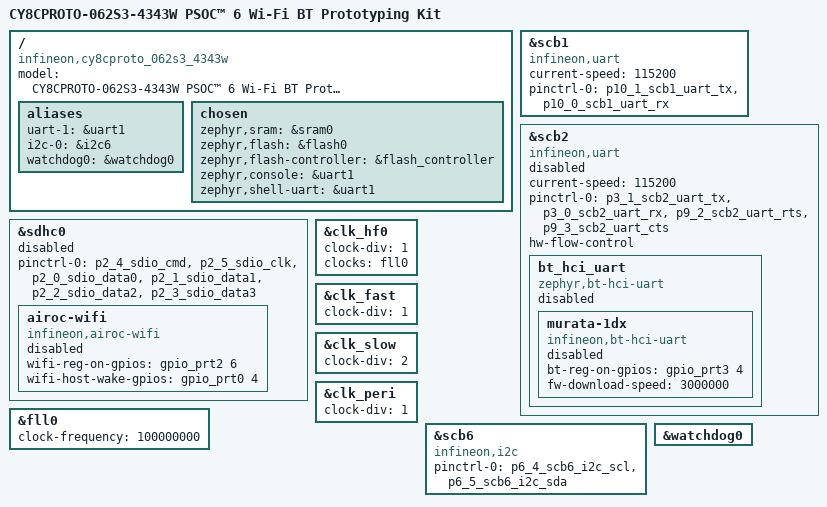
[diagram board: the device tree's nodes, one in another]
/*
 * Copyright (c) 2025 Hari Udayakumar <hariudkmr@gmail.com>
 * SPDX-License-Identifier: Apache-2.0
 */

/dts-v1/;
#include <infineon/cat1a/mpns/CY8C6245LQI_S3D72.dtsi>
#include <infineon/cat1a/system_clocks.dtsi>
#include "cy8cproto_062s3_4343w-common.dtsi"
#include "cy8cproto_062s3_4343w-pinctrl.dtsi"

/ {
	compatible = "infineon,cy8cproto_062s3_4343w", "cypress,PSOC6";
	model = "CY8CPROTO-062S3-4343W PSOC™ 6 Wi-Fi BT Prototyping Kit";

	aliases {
		uart-1 = &uart1;
		i2c-0 = &i2c6;
		watchdog0 = &watchdog0;
	};

	chosen {
		zephyr,sram = &sram0;
		zephyr,flash = &flash0;
		zephyr,flash-controller = &flash_controller;
		zephyr,console = &uart1;
		zephyr,shell-uart = &uart1;
	};
};

uart1: &scb1 {
	compatible = "infineon,uart";
	current-speed = <115200>;

	pinctrl-0 = <&p10_1_scb1_uart_tx &p10_0_scb1_uart_rx>;
	pinctrl-names = "default";
	status = "okay";
};

/*
 * The onboard Murata LBEE5KL1DX (CYW4343W) Wi-Fi/BT combo module is present
 * on this board, but Wi-Fi/BT is descoped from this board definition: the
 * Wi-Fi firmware blob alone (~420KB) does not fit alongside an application
 * in this SoC's 512KB internal flash. The HCI-UART and SDIO/Wi-Fi nodes
 * below are kept as disabled hardware-reference scaffolding only.
 */
uart2: &scb2 {
	compatible = "infineon,uart";

	/* The UART bus speed (current_speed) for zephyr_bt_uart should be the same
	 * as the default baudrate defined in CYW43xx firmware (default 115200).
	 */
	current-speed = <115200>;

	/* HCI-UART pins */
	pinctrl-0 = <&p3_1_scb2_uart_tx &p3_0_scb2_uart_rx &p9_2_scb2_uart_rts &p9_3_scb2_uart_cts>;
	pinctrl-names = "default";

	/* HW Flow control must be enabled for HCI H4 */
	hw-flow-control;
	status = "disabled";

	bt_hci_uart: bt_hci_uart {
		compatible = "zephyr,bt-hci-uart";
		status = "disabled";

		murata-1dx {
			compatible = "infineon,bt-hci-uart";
			bt-reg-on-gpios = <&gpio_prt3 4 GPIO_ACTIVE_HIGH>;

			/* Configuration UART speeds for firmware download (fw-download-speed)
			 * and HCI operation (hci-operation-speed).
			 * If hci-operation-speed or fw-download-speed are not defined in
			 * bt-hci{...} node, cyw43xx driver will use bus/current-speed as
			 * default speed.
			 */
			fw-download-speed = <3000000>;
			status = "disabled";
		};
	};
};

&sdhc0 {

	/* SDIO pins */
	pinctrl-0 = <&p2_4_sdio_cmd &p2_5_sdio_clk &p2_0_sdio_data0
		     &p2_1_sdio_data1 &p2_2_sdio_data2 &p2_3_sdio_data3>;
	pinctrl-names = "default";
	status = "disabled";

	/* Wi-Fi configuration */
	airoc-wifi {
		compatible = "infineon,airoc-wifi";

		/* Wi-Fi control gpios */
		wifi-reg-on-gpios = <&gpio_prt2 6 GPIO_ACTIVE_HIGH>;
		wifi-host-wake-gpios = <&gpio_prt0 4 GPIO_ACTIVE_HIGH>;
		status = "disabled";
	};
};

/* System clock configuration */
&fll0 {
	clock-frequency = <100000000>;
	status = "okay";
};

&clk_hf0 {
	clock-div = <1>;
	clocks = <&fll0>;
};

/* CM4 core clock = 100MHz
 * &fll clock-frequency / &clk_hf0 clock-div / &clk_fast clock-div = 100MHz / 1 / 1 = 100MHz
 */
&clk_fast {
	clock-div = <1>;
};

/* CM0+ core clock = 50MHz
 * &fll clock-frequency / &clk_hf0 clock-div / &clk_slow clock-div = 100MHz / 1 / 2 = 50MHz
 */
&clk_slow {
	clock-div = <2>;
};

/* PERI core clock = 100MHz
 * &fll clock-frequency / &clk_hf0 clock-div / &clk_peri clock-div = 100MHz / 1 / 1 = 100MHz
 */
&clk_peri {
	clock-div = <1>;
};

i2c6: &scb6 {
	compatible = "infineon,i2c";

	/* I2C pins */
	pinctrl-0 = <&p6_4_scb6_i2c_scl &p6_5_scb6_i2c_sda>;
	pinctrl-names = "default";
	status = "okay";
};

&watchdog0 {
	status = "okay";
};
